# STM32H7B3xx register map
File version: 1.0
Registers are 32-bit, access not given, reset 0x0 unless marked. A register's access mark holds for its fields unless they carry their own. Offsets are from the block's base; [hi:lo] are bit positions; {n}, {i} and the like mark numbered series.

## DLYB_SDMMC2
Base 0x48022800
Same registers: DLYB_OCTOSPI1 0x52006000, DLYB_SDMMC1 0x52008000, DLYB_OCTOSPI2 0x5200B000
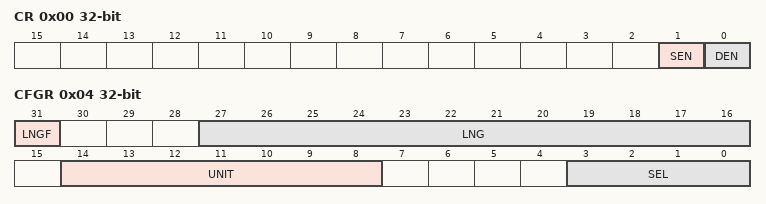
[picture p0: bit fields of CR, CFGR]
0x00 CR
  [1] SEN, [0] DEN
0x04 CFGR
  [31] LNGF, [27:16] LNG, [14:8] UNIT, [3:0] SEL

## BDMA1
Base 0x48022C00
Same registers: BDMA2 0x58025400
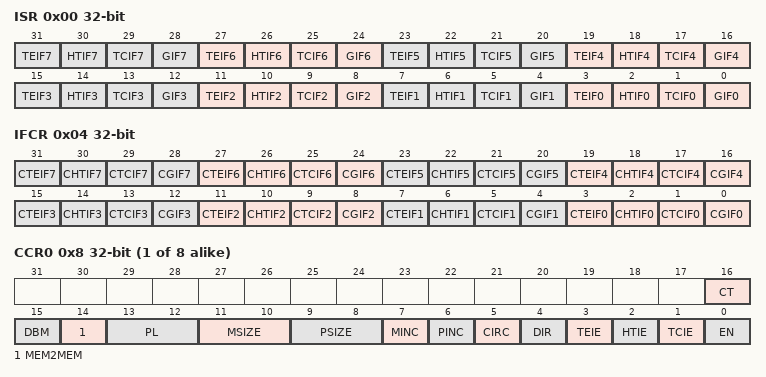
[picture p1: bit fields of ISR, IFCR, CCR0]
0x00 ISR
  [4n+3] TEIF{n} (n=0..7), [4n+2] HTIF{n} (n=0..7), [4n+1] TCIF{n} (n=0..7), [4n] GIF{n} (n=0..7)
0x04 IFCR
  [4n+3] CTEIF{n} (n=0..7), [4n+2] CHTIF{n} (n=0..7), [4n+1] CTCIF{n} (n=0..7), [4n] CGIF{n} (n=0..7)
{0x8+0x14*i} CCR{i} (i=0..7)
  [16] CT, [15] DBM, [14] MEM2MEM, [13:12] PL, [11:10] MSIZE, [9:8] PSIZE, [7] MINC, [6] PINC, [5] CIRC, [4] DIR, [3] TEIE, [2] HTIE, [1] TCIE, [0] EN
{0xC+0x14*i} CNDTR{i} (i=0..7)
  [15:0] NDT
{0x14+0x14*i} CPAR{i} (i=0..7)
  [31:0] PA
{0x20+0x14*i} CM0AR{i} (i=0..7)
  [31:0] MA
{0x30+0x14*i} CM1AR{i} (i=0..7)
  [31:0] MA

## LTDC
Base 0x50001000
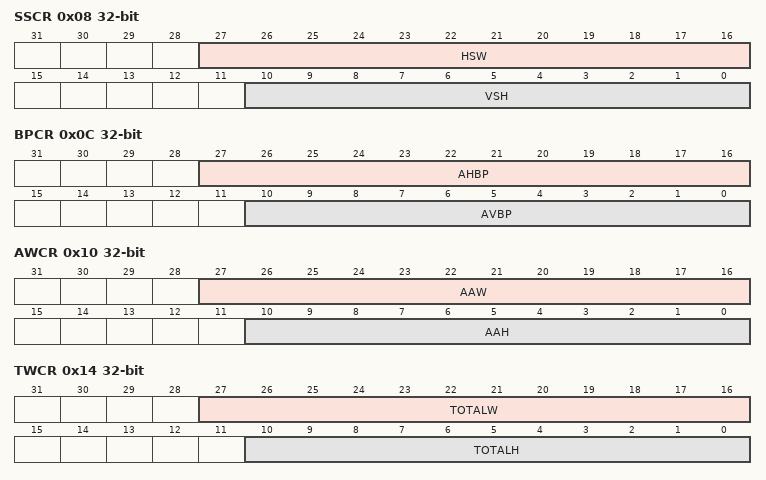
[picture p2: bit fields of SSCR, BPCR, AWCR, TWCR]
0x08 SSCR
  [27:16] HSW, [10:0] VSH
0x0C BPCR
  [27:16] AHBP, [10:0] AVBP
0x10 AWCR
  [27:16] AAW, [10:0] AAH
0x14 TWCR
  [27:16] TOTALW, [10:0] TOTALH
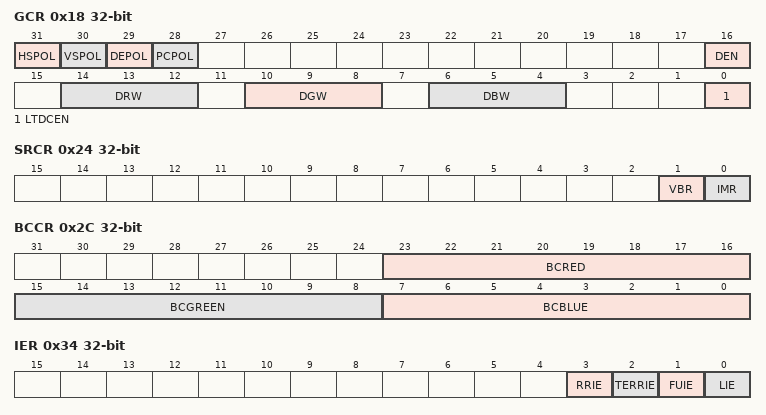
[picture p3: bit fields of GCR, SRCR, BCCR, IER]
0x18 GCR
  [31] HSPOL, [30] VSPOL, [29] DEPOL, [28] PCPOL, [16] DEN, [14:12] DRW, [10:8] DGW, [6:4] DBW, [0] LTDCEN
0x24 SRCR
  [1] VBR, [0] IMR
0x2C BCCR
  [23:16] BCRED, [15:8] BCGREEN, [7:0] BCBLUE
0x34 IER
  [3] RRIE, [2] TERRIE, [1] FUIE, [0] LIE
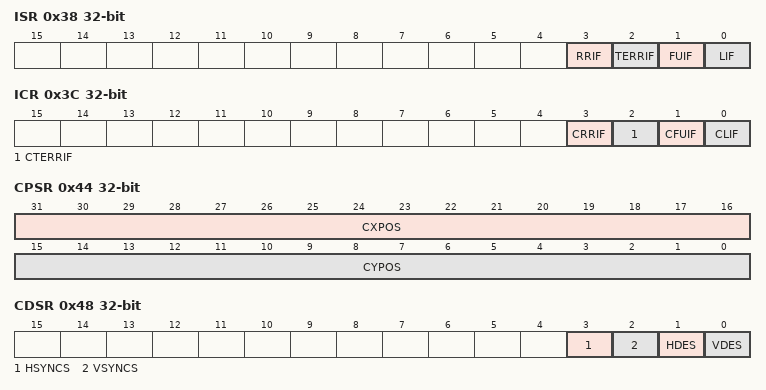
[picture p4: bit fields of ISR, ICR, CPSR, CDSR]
0x38 ISR
  [3] RRIF, [2] TERRIF, [1] FUIF, [0] LIF
0x3C ICR
  [3] CRRIF, [2] CTERRIF, [1] CFUIF, [0] CLIF
0x40 LIPCR
  [10:0] LIPOS
0x44 CPSR
  [31:16] CXPOS, [15:0] CYPOS
0x48 CDSR
  [3] HSYNCS, [2] VSYNCS, [1] HDES, [0] VDES
0x84 CR1
0x88 WHPCR1
0x90 WVPCR1
0x9C CKCR1
0xAC PFCR1
0xC0 CACR1
0xD8 DCCR1
0xF4 BFCR1
0x104 CR2
0x108 WHPCR2
0x110 WVPCR2
0x11C CFBAR1
0x11C CKCR2
0x12C PFCR2
0x140 CACR2
0x148 CFBLR1
0x158 DCCR2
0x174 BFCR2
0x178 CFBLNR1
0x19C CFBAR2
0x1B8 CLUTWR1
0x1C8 CFBLR2
0x1F8 CFBLNR2
0x238 CLUTWR2

## WWDG1
Base 0x50003000
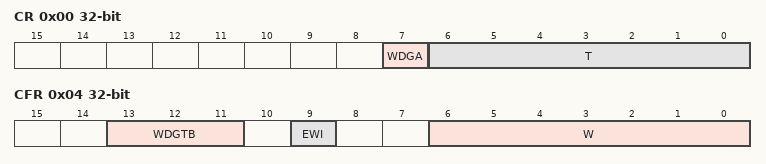
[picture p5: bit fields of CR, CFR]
0x00 CR
  [7] WDGA, [6:0] T
0x04 CFR
  [13:11] WDGTB, [9] EWI, [6:0] W
0x08 SR
  [0] EWIF

## GPV
Base 0x51000000
{0x1FC0+4i} AXI_PERIPH_ID_{i} (i=4..7)
{0x1FE0+4i} AXI_PERIPH_ID_{i} (i=0..3)
{0x1FF0+4i} AXI_COMP_ID_{i} (i=0..3)
{0x1008+0x1000*i} AXI_TARG{i}_FN_MOD_ISS_BM (i=1..10)
0x2024 AXI_TARG1_FN_MOD2
0x202C AXI_TARG1_FN_MOD_LB
0x2108 AXI_TARG1_FN_MOD
0x3024 AXI_TARG2_FN_MOD2
0x302C AXI_TARG2_FN_MOD_LB
0x3108 AXI_TARG2_FN_MOD
{0x1024+0x1000*i} AXI_TARG{i}_FN_MOD2 (i=7..10)
0x802C AXI_TARG7_FN_MOD_LB
{0x1108+0x1000*i} AXI_TARG{i}_FN_MOD (i=7..10)
0xC02C AXI_TARG10_FN_MOD_LB
0x42024 AXI_INI1_FN_MOD2
0x42028 AXI_INI1_FN_MOD_AHB
{0x41100+0x1000*i} AXI_INI{i}_READ_QOS (i=1..7)
{0x41104+0x1000*i} AXI_INI{i}_WRITE_QOS (i=1..7)
{0x41108+0x1000*i} AXI_INI{i}_FN_MOD (i=1..7)
0x44024 AXI_INI3_FN_MOD2
0x44028 AXI_INI3_FN_MOD_AHB
0x48024 AXI_INI7_FN_MOD2
0x48028 AXI_INI7_FN_MOD_AHB

## FLASH
Base 0x52002000
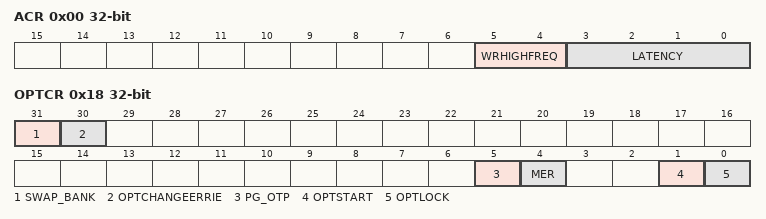
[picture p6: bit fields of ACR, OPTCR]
0x00 ACR
  [5:4] WRHIGHFREQ, [3:0] LATENCY
0x04 KEYR1
0x08 OPTKEYR
0x0C CR1
0x10 SR1
0x14 CCR1
0x18 OPTCR
  [31] SWAP_BANK, [30] OPTCHANGEERRIE, [5] PG_OTP, [4] MER, [1] OPTSTART, [0] OPTLOCK
0x1C OPTSR_CUR
0x20 OPTSR_PRG
0x24 OPTCCR
  [30] CLR_OPTCHANGEERR
0x28 PRAR_CUR1
0x2C PRAR_PRG1
0x30 SCAR_CUR1
0x34 SCAR_PRG1
0x38 WPSN_CUR1
0x3C WPSN_PRG1
0x40 BOOT_CUR
0x44 BOOT_PRG
0x50 CRCCR1
0x54 CRCSADD1
0x58 CRCEADD1
0x5C CRCDATA
  [31:0] CRC_DATA
0x60 ECC_FA1
0x68 OTPBL_CUR
0x6C OTPBL_PRG
0x104 KEYR2
0x10C CR2
0x110 SR2
0x114 CCR2
0x128 PRAR_CUR2
0x12C PRAR_PRG2
0x130 SCAR_CUR2
0x134 SCAR_PRG2
0x138 WPSN_CUR2
0x13C WPSN_PRG2
0x150 CRCCR2
0x154 CRCSADD2
0x158 CRCEADD2
0x15C CRCDATA2
0x160 ECC_FA2

## FMC_Bank1_R
Base 0x52004000
0x00 BTCR.0
0x04 BTCR.1
0x08 BTCR.2
0x0C BTCR.3
0x10 BTCR.4
0x14 BTCR.5
0x18 BTCR.6
0x1C BTCR.7

## FMC_Bank2_R
Base 0x52004060
0x00 PCR2
0x04 SR2
0x08 PMEM2
0x0C PATT2
0x14 ECCR2
